# ESP32-C3 register map
Vendor: ESPRESSIF SYSTEMS (SHANGHAI) CO., LTD.; Series: ESP32 C-Series; File version: 19
CPU: RV32IMC r0p0, little endian, no MPU, no FPU, 0 interrupt priority bits
Address unit: 32 bits
Registers are 32-bit, read-write, reset 0x0 unless marked. A register's access mark holds for its fields unless they carry their own. Offsets are from the block's base; [hi:lo] are bit positions; {n}, {i} and the like mark numbered series.

## RMT — Remote Control
Base 0x60016000
{0x0+4i} CH{i}DATA ro (i=0..3) — RMT_CH{i}DATA_REG.
  [31:0] CH{i}DATA — Reserved.
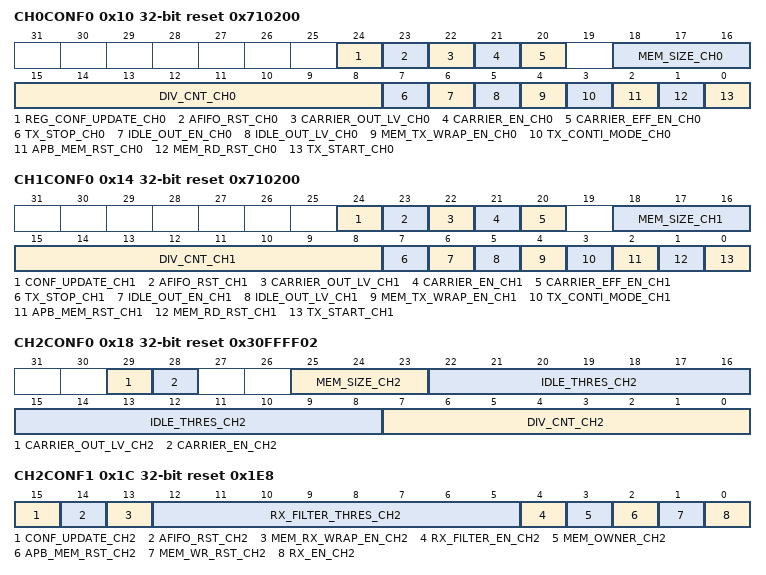
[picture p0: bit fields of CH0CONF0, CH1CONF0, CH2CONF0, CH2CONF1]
0x10 CH0CONF0 access per field reset 0x710200 — RMT_CH0CONF0_REG.
  [24] REG_CONF_UPDATE_CH0 wo — reg_reg_conf_update_ch0.
  [23] AFIFO_RST_CH0 wo — reg_afifo_rst_ch0.
  [22] CARRIER_OUT_LV_CH0 rw — reg_carrier_out_lv_ch0.
  [21] CARRIER_EN_CH0 rw — reg_carrier_en_ch0.
  [20] CARRIER_EFF_EN_CH0 rw — reg_carrier_eff_en_ch0.
  [18:16] MEM_SIZE_CH0 rw — reg_mem_size_ch0.
  [15:8] DIV_CNT_CH0 rw — reg_div_cnt_ch0.
  [7] TX_STOP_CH0 rw — reg_tx_stop_ch0.
  [6] IDLE_OUT_EN_CH0 rw — reg_idle_out_en_ch0.
  [5] IDLE_OUT_LV_CH0 rw — reg_idle_out_lv_ch0.
  [4] MEM_TX_WRAP_EN_CH0 rw — reg_mem_tx_wrap_en_ch0.
  [3] TX_CONTI_MODE_CH0 rw — reg_tx_conti_mode_ch0.
  [2] APB_MEM_RST_CH0 wo — reg_apb_mem_rst_ch0.
  [1] MEM_RD_RST_CH0 wo — reg_mem_rd_rst_ch0.
  [0] TX_START_CH0 wo — reg_tx_start_ch0.
0x14 CH1CONF0 access per field reset 0x710200 — RMT_CH1CONF0_REG.
  [24] CONF_UPDATE_CH1 wo — reg_conf_update_ch1.
  [23] AFIFO_RST_CH1 wo — reg_afifo_rst_ch1.
  [22] CARRIER_OUT_LV_CH1 rw — reg_carrier_out_lv_ch1.
  [21] CARRIER_EN_CH1 rw — reg_carrier_en_ch1.
  [20] CARRIER_EFF_EN_CH1 rw — reg_carrier_eff_en_ch1.
  [18:16] MEM_SIZE_CH1 rw — reg_mem_size_ch1.
  [15:8] DIV_CNT_CH1 rw — reg_div_cnt_ch1.
  [7] TX_STOP_CH1 rw — reg_tx_stop_ch1.
  [6] IDLE_OUT_EN_CH1 rw — reg_idle_out_en_ch1.
  [5] IDLE_OUT_LV_CH1 rw — reg_idle_out_lv_ch1.
  [4] MEM_TX_WRAP_EN_CH1 rw — reg_mem_tx_wrap_en_ch1.
  [3] TX_CONTI_MODE_CH1 rw — reg_tx_conti_mode_ch1.
  [2] APB_MEM_RST_CH1 wo — reg_apb_mem_rst_ch1.
  [1] MEM_RD_RST_CH1 wo — reg_mem_rd_rst_ch1.
  [0] TX_START_CH1 wo — reg_tx_start_ch1.
0x18 CH2CONF0 reset 0x30FFFF02 — RMT_CH2CONF0_REG.
  [29] CARRIER_OUT_LV_CH2 — reg_carrier_out_lv_ch2.
  [28] CARRIER_EN_CH2 — reg_carrier_en_ch2.
  [25:23] MEM_SIZE_CH2 — reg_mem_size_ch2.
  [22:8] IDLE_THRES_CH2 — reg_idle_thres_ch2.
  [7:0] DIV_CNT_CH2 — reg_div_cnt_ch2.
0x1C CH2CONF1 access per field reset 0x1E8 — RMT_CH2CONF1_REG.
  [15] CONF_UPDATE_CH2 wo — reg_conf_update_ch2.
  [14] AFIFO_RST_CH2 wo — reg_afifo_rst_ch2.
  [13] MEM_RX_WRAP_EN_CH2 rw — reg_mem_rx_wrap_en_ch2.
  [12:5] RX_FILTER_THRES_CH2 rw — reg_rx_filter_thres_ch2.
  [4] RX_FILTER_EN_CH2 rw — reg_rx_filter_en_ch2.
  [3] MEM_OWNER_CH2 rw — reg_mem_owner_ch2.
  [2] APB_MEM_RST_CH2 wo — reg_apb_mem_rst_ch2.
  [1] MEM_WR_RST_CH2 wo — reg_mem_wr_rst_ch2.
  [0] RX_EN_CH2 rw — reg_rx_en_ch2.
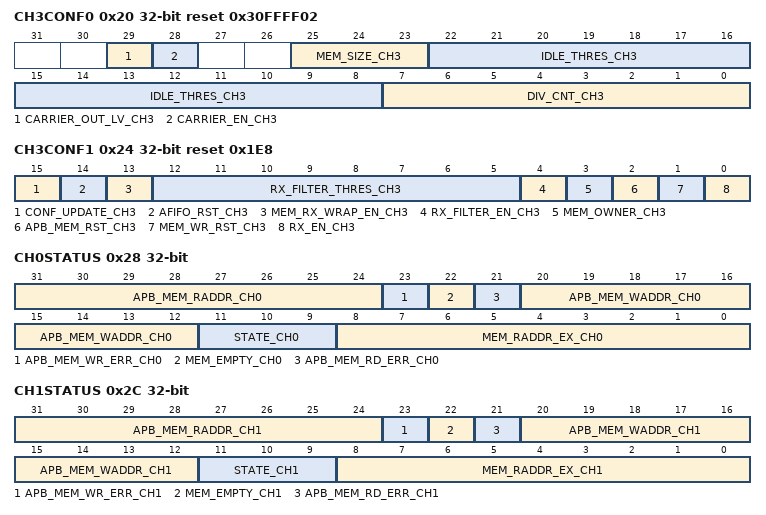
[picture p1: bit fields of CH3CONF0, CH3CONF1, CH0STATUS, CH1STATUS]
0x20 CH3CONF0 reset 0x30FFFF02 — RMT_CH3CONF0_REG.
  [29] CARRIER_OUT_LV_CH3 — reg_carrier_out_lv_ch3.
  [28] CARRIER_EN_CH3 — reg_carrier_en_ch3.
  [25:23] MEM_SIZE_CH3 — reg_mem_size_ch3.
  [22:8] IDLE_THRES_CH3 — reg_idle_thres_ch3.
  [7:0] DIV_CNT_CH3 — reg_div_cnt_ch3.
0x24 CH3CONF1 access per field reset 0x1E8 — RMT_CH3CONF1_REG.
  [15] CONF_UPDATE_CH3 wo — reg_conf_update_ch3.
  [14] AFIFO_RST_CH3 wo — reg_afifo_rst_ch3.
  [13] MEM_RX_WRAP_EN_CH3 rw — reg_mem_rx_wrap_en_ch3.
  [12:5] RX_FILTER_THRES_CH3 rw — reg_rx_filter_thres_ch3.
  [4] RX_FILTER_EN_CH3 rw — reg_rx_filter_en_ch3.
  [3] MEM_OWNER_CH3 rw — reg_mem_owner_ch3.
  [2] APB_MEM_RST_CH3 wo — reg_apb_mem_rst_ch3.
  [1] MEM_WR_RST_CH3 wo — reg_mem_wr_rst_ch3.
  [0] RX_EN_CH3 rw — reg_rx_en_ch3.
0x28 CH0STATUS ro — RMT_CH0STATUS_REG.
  [31:24] APB_MEM_RADDR_CH0 — reg_apb_mem_raddr_ch0.
  [23] APB_MEM_WR_ERR_CH0 — reg_apb_mem_wr_err_ch0.
  [22] MEM_EMPTY_CH0 — reg_mem_empty_ch0.
  [21] APB_MEM_RD_ERR_CH0 — reg_apb_mem_rd_err_ch0.
  [20:12] APB_MEM_WADDR_CH0 — reg_apb_mem_waddr_ch0.
  [11:9] STATE_CH0 — reg_state_ch0.
  [8:0] MEM_RADDR_EX_CH0 — reg_mem_raddr_ex_ch0.
0x2C CH1STATUS ro — RMT_CH1STATUS_REG.
  [31:24] APB_MEM_RADDR_CH1 — reg_apb_mem_raddr_ch1.
  [23] APB_MEM_WR_ERR_CH1 — reg_apb_mem_wr_err_ch1.
  [22] MEM_EMPTY_CH1 — reg_mem_empty_ch1.
  [21] APB_MEM_RD_ERR_CH1 — reg_apb_mem_rd_err_ch1.
  [20:12] APB_MEM_WADDR_CH1 — reg_apb_mem_waddr_ch1.
  [11:9] STATE_CH1 — reg_state_ch1.
  [8:0] MEM_RADDR_EX_CH1 — reg_mem_raddr_ex_ch1.
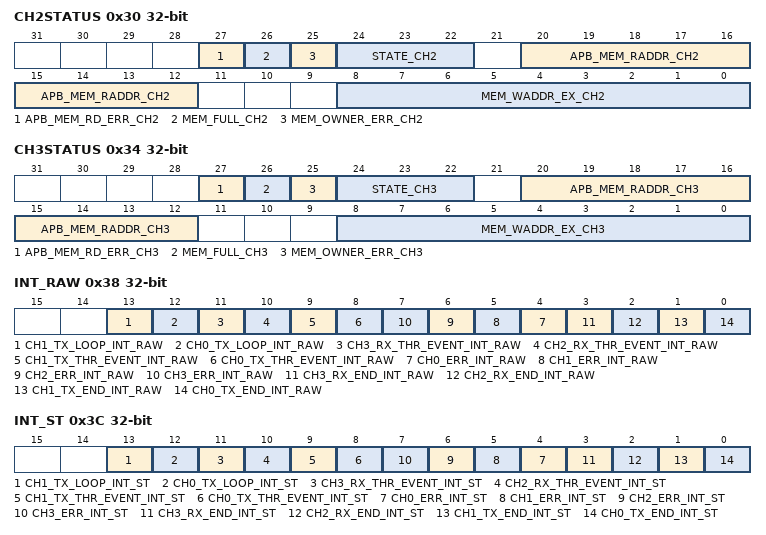
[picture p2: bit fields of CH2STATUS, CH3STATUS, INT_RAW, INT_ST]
0x30 CH2STATUS ro — RMT_CH2STATUS_REG.
  [27] APB_MEM_RD_ERR_CH2 — reg_apb_mem_rd_err_ch2.
  [26] MEM_FULL_CH2 — reg_mem_full_ch2.
  [25] MEM_OWNER_ERR_CH2 — reg_mem_owner_err_ch2.
  [24:22] STATE_CH2 — reg_state_ch2.
  [20:12] APB_MEM_RADDR_CH2 — reg_apb_mem_raddr_ch2.
  [8:0] MEM_WADDR_EX_CH2 — reg_mem_waddr_ex_ch2.
0x34 CH3STATUS ro — RMT_CH3STATUS_REG.
  [27] APB_MEM_RD_ERR_CH3 — reg_apb_mem_rd_err_ch3.
  [26] MEM_FULL_CH3 — reg_mem_full_ch3.
  [25] MEM_OWNER_ERR_CH3 — reg_mem_owner_err_ch3.
  [24:22] STATE_CH3 — reg_state_ch3.
  [20:12] APB_MEM_RADDR_CH3 — reg_apb_mem_raddr_ch3.
  [8:0] MEM_WADDR_EX_CH3 — reg_mem_waddr_ex_ch3.
0x38 INT_RAW — RMT_INT_RAW_REG.
  [13] CH1_TX_LOOP_INT_RAW — reg_ch1_tx_loop_int_raw.
  [12] CH0_TX_LOOP_INT_RAW — reg_ch0_tx_loop_int_raw.
  [11] CH3_RX_THR_EVENT_INT_RAW — reg_ch3_rx_thr_event_int_raw.
  [10] CH2_RX_THR_EVENT_INT_RAW — reg_ch2_rx_thr_event_int_raw.
  [9] CH1_TX_THR_EVENT_INT_RAW — reg_ch1_tx_thr_event_int_raw.
  [8] CH0_TX_THR_EVENT_INT_RAW — reg_ch0_tx_thr_event_int_raw.
  [n+4] CH{n}_ERR_INT_RAW (n=0..3) — reg_ch{n}_err_int_raw.
  [3] CH3_RX_END_INT_RAW — reg_ch3_rx_end_int_raw.
  [2] CH2_RX_END_INT_RAW — reg_ch2_rx_end_int_raw.
  [1] CH1_TX_END_INT_RAW — reg_ch1_tx_end_int_raw.
  [0] CH0_TX_END_INT_RAW — reg_ch0_tx_end_int_raw.
0x3C INT_ST ro — RMT_INT_ST_REG.
  [13] CH1_TX_LOOP_INT_ST — reg_ch1_tx_loop_int_st.
  [12] CH0_TX_LOOP_INT_ST — reg_ch0_tx_loop_int_st.
  [11] CH3_RX_THR_EVENT_INT_ST — reg_ch3_rx_thr_event_int_st.
  [10] CH2_RX_THR_EVENT_INT_ST — reg_ch2_rx_thr_event_int_st.
  [9] CH1_TX_THR_EVENT_INT_ST — reg_ch1_tx_thr_event_int_st.
  [8] CH0_TX_THR_EVENT_INT_ST — reg_ch0_tx_thr_event_int_st.
  [n+4] CH{n}_ERR_INT_ST (n=0..3) — reg_ch{n}_err_int_st.
  [3] CH3_RX_END_INT_ST — reg_ch3_rx_end_int_st.
  [2] CH2_RX_END_INT_ST — reg_ch2_rx_end_int_st.
  [1] CH1_TX_END_INT_ST — reg_ch1_tx_end_int_st.
  [0] CH0_TX_END_INT_ST — reg_ch0_tx_end_int_st.
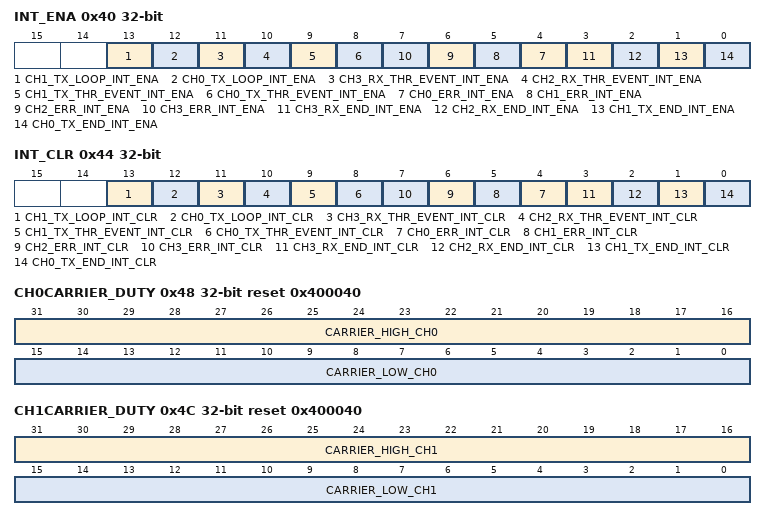
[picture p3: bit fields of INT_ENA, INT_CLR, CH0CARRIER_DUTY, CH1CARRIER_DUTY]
0x40 INT_ENA — RMT_INT_ENA_REG.
  [13] CH1_TX_LOOP_INT_ENA — reg_ch1_tx_loop_int_ena.
  [12] CH0_TX_LOOP_INT_ENA — reg_ch0_tx_loop_int_ena.
  [11] CH3_RX_THR_EVENT_INT_ENA — reg_ch3_rx_thr_event_int_ena.
  [10] CH2_RX_THR_EVENT_INT_ENA — reg_ch2_rx_thr_event_int_ena.
  [9] CH1_TX_THR_EVENT_INT_ENA — reg_ch1_tx_thr_event_int_ena.
  [8] CH0_TX_THR_EVENT_INT_ENA — reg_ch0_tx_thr_event_int_ena.
  [n+4] CH{n}_ERR_INT_ENA (n=0..3) — reg_ch{n}_err_int_ena.
  [3] CH3_RX_END_INT_ENA — reg_ch3_rx_end_int_ena.
  [2] CH2_RX_END_INT_ENA — reg_ch2_rx_end_int_ena.
  [1] CH1_TX_END_INT_ENA — reg_ch1_tx_end_int_ena.
  [0] CH0_TX_END_INT_ENA — reg_ch0_tx_end_int_ena.
0x44 INT_CLR wo — RMT_INT_CLR_REG.
  [13] CH1_TX_LOOP_INT_CLR — reg_ch1_tx_loop_int_clr.
  [12] CH0_TX_LOOP_INT_CLR — reg_ch0_tx_loop_int_clr.
  [11] CH3_RX_THR_EVENT_INT_CLR — reg_ch3_rx_thr_event_int_clr.
  [10] CH2_RX_THR_EVENT_INT_CLR — reg_ch2_rx_thr_event_int_clr.
  [9] CH1_TX_THR_EVENT_INT_CLR — reg_ch1_tx_thr_event_int_clr.
  [8] CH0_TX_THR_EVENT_INT_CLR — reg_ch0_tx_thr_event_int_clr.
  [n+4] CH{n}_ERR_INT_CLR (n=0..3) — reg_ch{n}_err_int_clr.
  [3] CH3_RX_END_INT_CLR — reg_ch3_rx_end_int_clr.
  [2] CH2_RX_END_INT_CLR — reg_ch2_rx_end_int_clr.
  [1] CH1_TX_END_INT_CLR — reg_ch1_tx_end_int_clr.
  [0] CH0_TX_END_INT_CLR — reg_ch0_tx_end_int_clr.
0x48 CH0CARRIER_DUTY reset 0x400040 — RMT_CH0CARRIER_DUTY_REG.
  [31:16] CARRIER_HIGH_CH0 — reg_carrier_high_ch0.
  [15:0] CARRIER_LOW_CH0 — reg_carrier_low_ch0.
0x4C CH1CARRIER_DUTY reset 0x400040 — RMT_CH1CARRIER_DUTY_REG.
  [31:16] CARRIER_HIGH_CH1 — reg_carrier_high_ch1.
  [15:0] CARRIER_LOW_CH1 — reg_carrier_low_ch1.
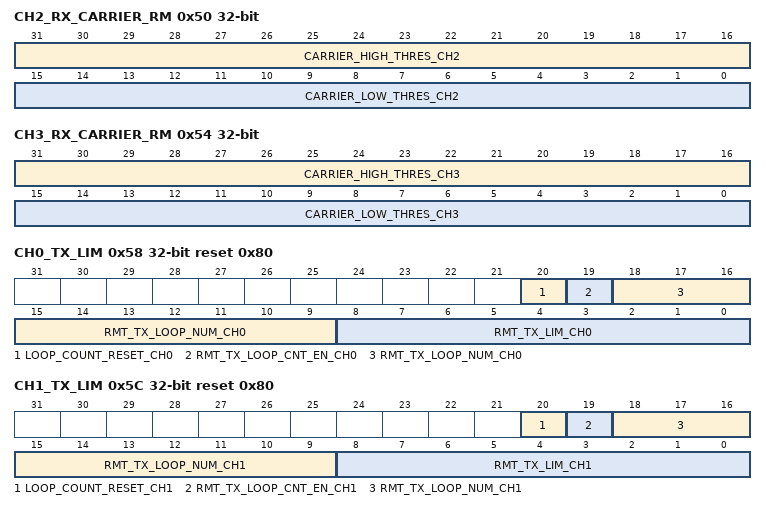
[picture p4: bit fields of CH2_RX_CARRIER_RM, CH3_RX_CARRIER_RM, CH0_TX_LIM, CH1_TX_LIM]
0x50 CH2_RX_CARRIER_RM — RMT_CH2_RX_CARRIER_RM_REG.
  [31:16] CARRIER_HIGH_THRES_CH2 — reg_carrier_high_thres_ch2.
  [15:0] CARRIER_LOW_THRES_CH2 — reg_carrier_low_thres_ch2.
0x54 CH3_RX_CARRIER_RM — RMT_CH3_RX_CARRIER_RM_REG.
  [31:16] CARRIER_HIGH_THRES_CH3 — reg_carrier_high_thres_ch3.
  [15:0] CARRIER_LOW_THRES_CH3 — reg_carrier_low_thres_ch3.
0x58 CH0_TX_LIM access per field reset 0x80 — RMT_CH0_TX_LIM_REG.
  [20] LOOP_COUNT_RESET_CH0 wo — reg_loop_count_reset_ch0.
  [19] RMT_TX_LOOP_CNT_EN_CH0 rw — reg_rmt_tx_loop_cnt_en_ch0.
  [18:9] RMT_TX_LOOP_NUM_CH0 rw — reg_rmt_tx_loop_num_ch0.
  [8:0] RMT_TX_LIM_CH0 rw — reg_rmt_tx_lim_ch0.
0x5C CH1_TX_LIM access per field reset 0x80 — RMT_CH1_TX_LIM_REG.
  [20] LOOP_COUNT_RESET_CH1 wo — reg_loop_count_reset_ch1.
  [19] RMT_TX_LOOP_CNT_EN_CH1 rw — reg_rmt_tx_loop_cnt_en_ch1.
  [18:9] RMT_TX_LOOP_NUM_CH1 rw — reg_rmt_tx_loop_num_ch1.
  [8:0] RMT_TX_LIM_CH1 rw — reg_rmt_tx_lim_ch1.
0x60 CH2_RX_LIM reset 0x80 — RMT_CH2_RX_LIM_REG.
  [8:0] RMT_RX_LIM_CH2 — reg_rmt_rx_lim_ch2.
0x64 CH3_RX_LIM reset 0x80 — RMT_CH3_RX_LIM_REG.
  [8:0] RMT_RX_LIM_CH3 — reg_rmt_rx_lim_ch3.
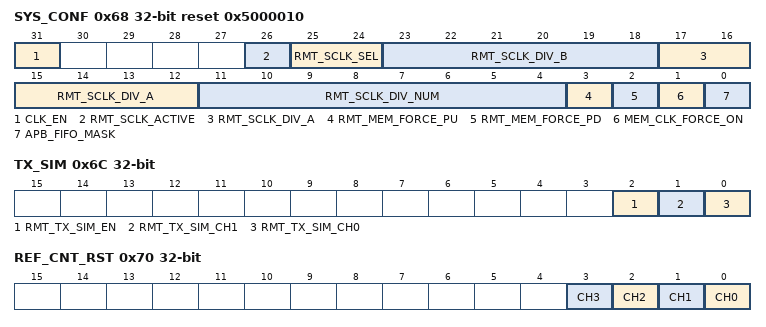
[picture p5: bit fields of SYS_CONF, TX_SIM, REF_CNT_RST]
0x68 SYS_CONF reset 0x5000010 — RMT_SYS_CONF_REG.
  [31] CLK_EN — reg_clk_en.
  [26] RMT_SCLK_ACTIVE — reg_rmt_sclk_active.
  [25:24] RMT_SCLK_SEL — reg_rmt_sclk_sel.
  [23:18] RMT_SCLK_DIV_B — reg_rmt_sclk_div_b.
  [17:12] RMT_SCLK_DIV_A — reg_rmt_sclk_div_a.
  [11:4] RMT_SCLK_DIV_NUM — reg_rmt_sclk_div_num.
  [3] RMT_MEM_FORCE_PU — reg_rmt_mem_force_pu.
  [2] RMT_MEM_FORCE_PD — reg_rmt_mem_force_pd.
  [1] MEM_CLK_FORCE_ON — reg_mem_clk_force_on.
  [0] APB_FIFO_MASK — reg_apb_fifo_mask.
0x6C TX_SIM — RMT_TX_SIM_REG.
  [2] RMT_TX_SIM_EN — reg_rmt_tx_sim_en.
  [1] RMT_TX_SIM_CH1 — reg_rmt_tx_sim_ch1.
  [0] RMT_TX_SIM_CH0 — reg_rmt_tx_sim_ch0.
0x70 REF_CNT_RST wo — RMT_REF_CNT_RST_REG.
  [n] CH{n} (n=0..3) — reg_ref_cnt_rst_ch{n}.
0xCC DATE reset 0x2006231 — RMT_DATE_REG.
  [27:0] RMT_DATE — reg_rmt_date.
